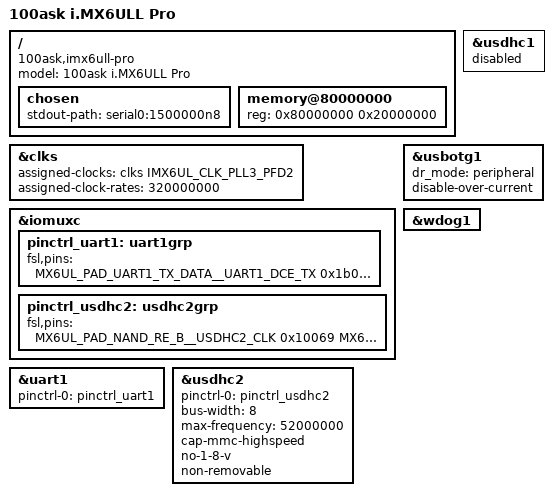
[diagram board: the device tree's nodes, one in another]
// SPDX-License-Identifier: (GPL-2.0 OR MIT)
/dts-v1/;

#include "imx6ull.dtsi"

/ {
	model = "100ask i.MX6ULL Pro";
	compatible = "100ask,imx6ull-pro", "fsl,imx6ull";

	chosen {
		stdout-path = "serial0:1500000n8";
	};

	memory@80000000 {
		device_type = "memory";
		reg = <0x80000000 0x20000000>;
	};
};

&clks {
	assigned-clocks = <&clks IMX6UL_CLK_PLL3_PFD2>;
	assigned-clock-rates = <320000000>;
};

&iomuxc {
	pinctrl_uart1: uart1grp {
		fsl,pins = <
			MX6UL_PAD_UART1_TX_DATA__UART1_DCE_TX 0x1b0b1
			MX6UL_PAD_UART1_RX_DATA__UART1_DCE_RX 0x1b0b1
		>;
	};

	pinctrl_usdhc2: usdhc2grp {
		fsl,pins = <
			MX6UL_PAD_NAND_RE_B__USDHC2_CLK     0x10069
			MX6UL_PAD_NAND_WE_B__USDHC2_CMD     0x17059
			MX6UL_PAD_NAND_DATA00__USDHC2_DATA0 0x17059
			MX6UL_PAD_NAND_DATA01__USDHC2_DATA1 0x17059
			MX6UL_PAD_NAND_DATA02__USDHC2_DATA2 0x17059
			MX6UL_PAD_NAND_DATA03__USDHC2_DATA3 0x17059
			MX6UL_PAD_NAND_DATA04__USDHC2_DATA4 0x17059
			MX6UL_PAD_NAND_DATA05__USDHC2_DATA5 0x17059
			MX6UL_PAD_NAND_DATA06__USDHC2_DATA6 0x17059
			MX6UL_PAD_NAND_DATA07__USDHC2_DATA7 0x17059
		>;
	};
};

&uart1 {
	pinctrl-names = "default";
	pinctrl-0 = <&pinctrl_uart1>;
	status = "okay";
};

/* Keep the SoC's mmc1 alias: the legacy clock driver uses this index. */
&usdhc1 {
	status = "disabled";
};

&usdhc2 {
	pinctrl-names = "default";
	pinctrl-0 = <&pinctrl_usdhc2>;
	bus-width = <8>;
	max-frequency = <52000000>;
	cap-mmc-highspeed;
	no-1-8-v;
	non-removable;
	status = "okay";
};

/* USB OTG1 connects to the host for fastboot. It does not supply VBUS. */
&usbotg1 {
	dr_mode = "peripheral";
	disable-over-current;
	status = "okay";
};

&wdog1 {
	status = "okay";
};
